VERSION ""

NS_ :

BS_:

BU_: DBG DRIVER IO MOTOR SENSOR GEO

BO_ 100 DRIVER_HEARTBEAT: 1 DRIVER
 SG_ DRIVER_HEARTBEAT_cmd : 0|8@1+ (1,0) [0|0] "" SENSOR,MOTOR

BO_ 101 SENSOR_HEARTBEAT: 1 SENSOR
 SG_ SENSOR_HEARTBEAT_cmd: 0|8@1+ (1,0) [0|0] "" DRIVER,GEO

BO_ 102 GEO_HEARTBEAT: 1 GEO
 SG_ GEO_HEARTBEAT_cmd: 0|8@1+ (1,0) [0|0] "" DRIVER,SENSOR

BO_ 103 MOTOR_HEARTBEAT: 1 MOTOR
 SG_ MOTOR_HEARTBEAT_cmd: 0|8@1+ (1,0) [0|0] "" DRIVER

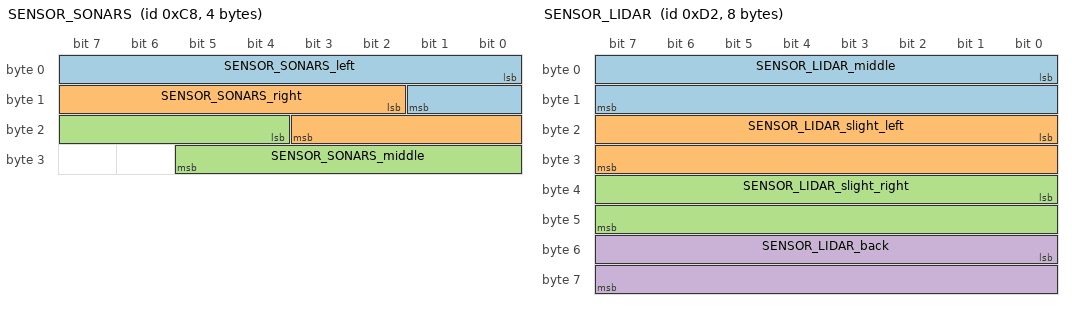
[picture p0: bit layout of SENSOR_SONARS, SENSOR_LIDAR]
BO_ 200 SENSOR_SONARS: 4 SENSOR
 SG_ SENSOR_SONARS_left : 0|10@1+ (1,0) [0|800] "inch" DRIVER
 SG_ SENSOR_SONARS_right : 10|10@1+ (1,0) [0|0] "inch" DRIVER
 SG_ SENSOR_SONARS_middle : 20|10@1+ (1,0) [0|0] "inch" DRIVER

BO_ 210 SENSOR_LIDAR: 8 SENSOR
 SG_ SENSOR_LIDAR_middle: 0|16@1+ (1,0) [0|0] "" DRIVER
 SG_ SENSOR_LIDAR_slight_left: 16|16@1+ (1,0) [0|0] "" DRIVER
 SG_ SENSOR_LIDAR_slight_right: 32|16@1+ (1,0) [0|0] "" DRIVER
 SG_ SENSOR_LIDAR_back: 48|16@1+ (1,0) [0|0] "" DRIVER

BO_ 220 SENSOR_BT_COORDINATES: 8 SENSOR
 SG_ SENSOR_BT_COORDINATES_latitude: 0|32@1+ (0.0001,0) [0|0] "" GEO
 SG_ SENSOR_BT_COORDINATES_longitude: 32|32@1+ (0.0001,0) [0|0] "" GEO

BO_ 300 GEO_DEGREE: 8 GEO
 SG_ GEO_DEGREE_current: 0|32@1+ (0.1,0) [0|0] "" DRIVER
 SG_ GEO_DEGREE_required: 32|32@1+ (0.1,0) [0|0] "" DRIVER

BO_ 400 DRIVER_STEERING: 8 DRIVER
 SG_ DRIVER_STEERING_direction: 0|8@1- (1,0) [-2|2] "" MOTOR
 SG_ DRIVER_STEERING_speed: 8|32@1+ (0.1, 0) [0|60] "kph" MOTOR

BO_ 500 MOTOR_INFO: 4 MOTOR
 SG_ MOTOR_INFO_rpm: 0|32@1+ (0.1,0) [0|0] "" DRIVER

CM_ BU_ DRIVER "The driver controller driving the car";
CM_ BU_ MOTOR "The motor controller of the car";
CM_ BU_ SENSOR "The sensor controller of the car";
CM_ BU_ GEO "The geo controller of the car";

CM_ BO_ 100 "Driver Sync message used to synchronize the controllers";
CM_ BO_ 101 "Sensor Sync message used to synchronize the controllers";
CM_ BO_ 102 "Geo Sync message used to synchronize the controllers";
CM_ BO_ 103 "Motor Sync message used to synchronize the controllers";
CM_ BO_ 200 "Ultrasonic Sensor values sent by Sensor Node";
CM_ BO_ 210 "Lidar Sector values sent by Sensor Node";
CM_ BO_ 220 "Coordinate BT values sent by Sensor Node";
CM_ BO_ 300 "Current and computed degree values sent by Geo Node";
CM_ BO_ 400 "Steering direction and speed values sent by Driver Node";
CM_ BO_ 500 "Information values sent by Motor Node";

CM_ SG_ 100 DRIVER_HEARTBEAT_cmd "Heartbeat command from the driver";
CM_ SG_ 101 SENSOR_HEARTBEAT_cmd "Heartbeat command from the sensor";
CM_ SG_ 102 GEO_HEARTBEAT_cmd "Heartbeat command from the geological node";
CM_ SG_ 103 MOTOR_HEARTBEAT_cmd "Heartbeat command from the motor";

CM_ SG_ 200 SENSOR_SONARS_left "Ultrasonic Sensor attached to the left side";
CM_ SG_ 200 SENSOR_SONARS_right "Ultrasonic Sensor attached to the right side";
CM_ SG_ 200 SENSOR_SONARS_middle "Ultrasonic Sensor attached to the middle";

CM_ SG_ 210 SENSOR_LIDAR_middle "Lidar sensing the middle sector (-15 to 15)";
CM_ SG_ 210 SENSOR_LIDAR_slight_left "Lidar sensing the slight left sector (-45 to -15)";
CM_ SG_ 210 SENSOR_LIDAR_slight_right "Lidar sensing the slight right sector (15 to 45)";
CM_ SG_ 210 SENSOR_LIDAR_back "Lidar sensing the back of the car (165 to 195)";

CM_ SG_ 220 SENSOR_BT_COORDINATES_latitude "Destination Latitude received over Bluetooth";
CM_ SG_ 220 SENSOR_BT_COORDINATES_longitude "Destination Longitude received over Bluetooth";

CM_ SG_ 300 GEO_DEGREE_current "Current Geo Degree relative to true north";
CM_ SG_ 300 GEO_DEGREE_required "Calculated Geo Degree computed by Haversine Formula";

CM_ SG_ 400 DRIVER_STEERING_direction "Calculated Driver Steering values for Motor";
CM_ SG_ 400 DRIVER_STEERING_speed "Calculated Driver speed values for Motor";

CM_ SG_ 500 MOTOR_INFO_rpm "Feedback RPM (speed) sent by Motor";

BA_DEF_ "BusType" STRING ;
BA_DEF_ BO_ "GenMsgCycleTime" INT 0 0;
BA_DEF_ SG_ "FieldType" STRING ;

BA_DEF_DEF_ "BusType" "CAN";
BA_DEF_DEF_ "FieldType" "";
BA_DEF_DEF_ "GenMsgCycleTime" 0;

BA_ "GenMsgCycleTime" BO_ 100 1000;
BA_ "GenMsgCycleTime" BO_ 200 50;

BA_ "FieldType" SG_ 100 DRIVER_HEARTBEAT_cmd "DRIVER_HEARTBEAT_cmd";
BA_ "FieldType" SG_ 101 SENSOR_HEARTBEAT_cmd "SENSOR_HEARTBEAT_cmd";
BA_ "FieldType" SG_ 102 GEO_HEARTBEAT_cmd "GEO_HEARTBEAT_cmd";
BA_ "FieldType" SG_ 103 MOTOR_HEARTBEAT_cmd "MOTOR_HEARTBEAT_cmd";

VAL_ 100 DRIVER_HEARTBEAT_cmd 2 "DRIVER_HEARTBEAT_cmd_REBOOT" 1 "DRIVER_HEARTBEAT_cmd_SYNC" 0 "DRIVER_HEARTBEAT_cmd_NOOP" ;
VAL_ 101 SENSOR_HEARTBEAT_cmd 2 "SENSOR_HEARTBEAT_cmd_REBOOT" 1 "SENSOR_HEARTBEAT_cmd_SYNC" 0 "SENSOR_HEARTBEAT_cmd_NOOP" ;
VAL_ 102 GEO_HEARTBEAT_cmd 2 "GEO_HEARTBEAT_cmd_REBOOT" 1 "GEO_HEARTBEAT_cmd_SYNC" 0 "GEO_HEARTBEAT_cmd_NOOP" ;
VAL_ 103 MOTOR_HEARTBEAT_cmd 2 "MOTOR_HEARTBEAT_cmd_REBOOT" 1 "MOTOR_HEARTBEAT_cmd_SYNC" 0 "MOTOR_HEARTBEAT_cmd_NOOP" ;
